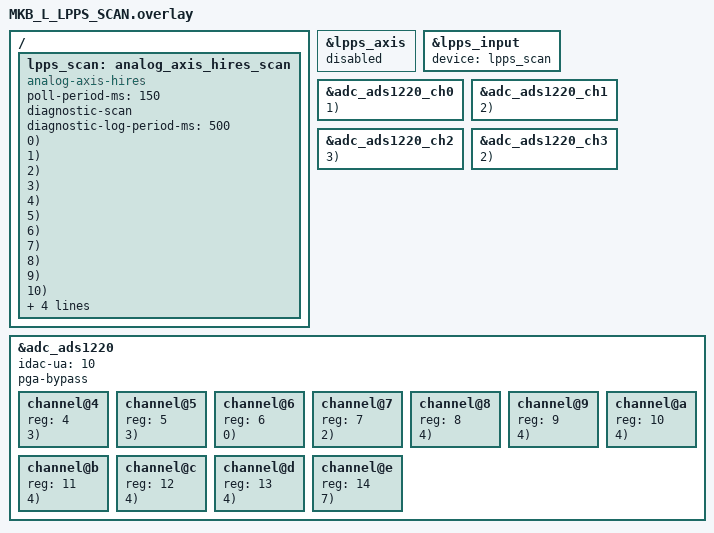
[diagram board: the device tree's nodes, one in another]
#include "MKB_L_LPPS.overlay"

/*
 * Diagnostic-only shield. It samples every ADS1220 MUX selection at gain 1
 * and emits two compact ADSSCAN records every 500 ms. No pointer events are
 * generated.
 */

#define ADS_SCAN_CHANNEL_PROPERTIES(_positive, _negative) \
	zephyr,resolution = <24>; \
	zephyr,gain = "ADC_GAIN_1"; \
	zephyr,reference = "ADC_REF_INTERNAL"; \
	zephyr,acquisition-time = <175>; \
	zephyr,input-positive = <_positive>; \
	zephyr,input-negative = <_negative>; \
	zephyr,current-source-pin = [05 00]

#define LPPS_SCAN_AXIS(_name, _channel) \
	_name { \
		status = "okay"; \
		io-channels = <&adc_ads1220 _channel>; \
		in-min = <(-8388607)>; \
		in-max = <8388607>; \
		in-deadzone = <0>; \
		out-min = <(-1)>; \
		out-max = <1>; \
		monitor-only; \
		zephyr,axis-type = <INPUT_EV_REL>; \
		zephyr,axis = <INPUT_REL_X>; \
	}

&lpps_axis {
	status = "disabled";
};

&lpps_input {
	device = <&lpps_scan>;
};

/ {
	lpps_scan: analog_axis_hires_scan {
		compatible = "analog-axis-hires";
		status = "okay";
		poll-period-ms = <150>;
		diagnostic-scan;
		diagnostic-log-period-ms = <500>;

		LPPS_SCAN_AXIS(mux_0, 0);
		LPPS_SCAN_AXIS(mux_1, 1);
		LPPS_SCAN_AXIS(mux_2, 2);
		LPPS_SCAN_AXIS(mux_3, 3);
		LPPS_SCAN_AXIS(mux_4, 4);
		LPPS_SCAN_AXIS(mux_5, 5);
		LPPS_SCAN_AXIS(mux_6, 6);
		LPPS_SCAN_AXIS(mux_7, 7);
		LPPS_SCAN_AXIS(mux_8, 8);
		LPPS_SCAN_AXIS(mux_9, 9);
		LPPS_SCAN_AXIS(mux_10, 10);
		LPPS_SCAN_AXIS(mux_11, 11);
		LPPS_SCAN_AXIS(mux_12, 12);
		LPPS_SCAN_AXIS(mux_13, 13);
		LPPS_SCAN_AXIS(mux_14, 14);
	};
};

&adc_ads1220_ch0 {
	ADS_SCAN_CHANNEL_PROPERTIES(0, 1);
};

&adc_ads1220_ch1 {
	ADS_SCAN_CHANNEL_PROPERTIES(0, 2);
};

&adc_ads1220_ch2 {
	ADS_SCAN_CHANNEL_PROPERTIES(0, 3);
};

&adc_ads1220_ch3 {
	ADS_SCAN_CHANNEL_PROPERTIES(1, 2);
};

&adc_ads1220 {
	idac-ua = <10>;
	pga-bypass;

	channel@4 {
		reg = <4>;
		ADS_SCAN_CHANNEL_PROPERTIES(1, 3);
	};
	channel@5 {
		reg = <5>;
		ADS_SCAN_CHANNEL_PROPERTIES(2, 3);
	};
	channel@6 {
		reg = <6>;
		ADS_SCAN_CHANNEL_PROPERTIES(1, 0);
	};
	channel@7 {
		reg = <7>;
		ADS_SCAN_CHANNEL_PROPERTIES(3, 2);
	};
	channel@8 {
		reg = <8>;
		ADS_SCAN_CHANNEL_PROPERTIES(0, 4);
	};
	channel@9 {
		reg = <9>;
		ADS_SCAN_CHANNEL_PROPERTIES(1, 4);
	};
	channel@a {
		reg = <10>;
		ADS_SCAN_CHANNEL_PROPERTIES(2, 4);
	};
	channel@b {
		reg = <11>;
		ADS_SCAN_CHANNEL_PROPERTIES(3, 4);
	};
	channel@c {
		reg = <12>;
		ADS_SCAN_CHANNEL_PROPERTIES(5, 4);
	};
	channel@d {
		reg = <13>;
		ADS_SCAN_CHANNEL_PROPERTIES(6, 4);
	};
	channel@e {
		reg = <14>;
		ADS_SCAN_CHANNEL_PROPERTIES(7, 7);
	};
};
